# MB9BFD1xT register map
File version: 1.7
Registers are 32-bit, read-write, reset 0x0 unless marked. A register's access mark holds for its fields unless they carry their own. Offsets are from the block's base; [hi:lo] are bit positions; 'fields as' and 'values as' point back to an identical list.

## FLASH_IF — Flash Memory
Base 0x40000000
0x00 FASZR reset 0x2 — Flash Access Size Register
  [1:0] ASZ — Flash Access Size
0x04 FRWTR reset 0x2 — Flash Read Wait Register
  [1:0] RWT — Read Wait Cycle
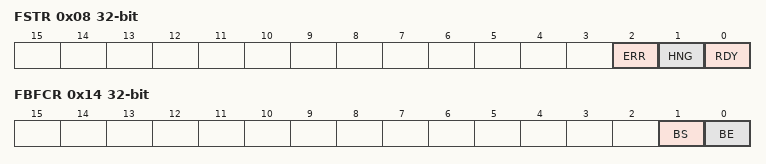
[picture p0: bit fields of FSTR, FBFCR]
0x08 FSTR ro — Flash Status Register
  [2] ERR rw — Flash ECC Error
  [1] HNG — Flash Hang flag
  [0] RDY — Flash Rdy
0x10 FSYNDN — Flash Sync Down Register
  [2:0] SD — Flash Sync
0x14 FBFCR — Flash Buffer Control Register
  [1] BS ro — Buffer Status
  [0] BE — Buffer Enable
0x100 CRTRMM ro reset not defined — CR Trimming Data Mirror Register
  [9:0] TRMM — CR Trimming Data Mirror

## CRTRIM — CR Trimming Registers
Base 0x4002E000
0x00 MCR_PSR 8-bit reset 0x1 — High-speed CR oscillation Frequency Division Setup Register
  [1:0] CSR — High-speed CR oscillation frequency division ratio setting bits
0x04 MCR_FTRM 16-bit reset 0x7F — High-speed CR oscillation Frequency Trimming Register
  [7:0] TRD — Frequency trimming setup bits
0x0C MCR_RLR reset 0x1 — High-Speed CR Oscillation Register Write-Protect Register
  [31:0] TRMLCK — Register write-protect bits

## SWWDT — Software Watchdog Timer
Base 0x40012000
0x00 WDOGLOAD reset 0xFFFFFFFF — Software Watchdog Timer Load Register
0x04 WDOGVALUE ro reset 0xFFFFFFFF — Software Watchdog Timer Value Register
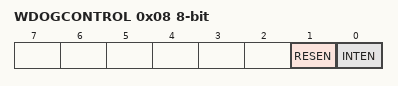
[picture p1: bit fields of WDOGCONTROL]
0x08 WDOGCONTROL 8-bit — Software Watchdog Timer Control Register
  [1] RESEN — Reset enable bit of the software watchdog
  [0] INTEN — Interrupt and counter enable bit of the software watchdog
0x0C WDOGINTCLR reset 0xFFFFFFFF — Software Watchdog Timer Clear Register
0x10 WDOGRIS 8-bit ro — Software Watchdog Timer Interrupt Status Register
  [0] RIS — Software watchdog interrupt status bit
0xC00 WDOGLOCK — Software Watchdog Timer Lock Register

## HWWDT — Hardware Watchdog Timer
Base 0x40011000
0x00 WDG_LDR reset 0xFFFF — Hardware Watchdog Timer Load Register
0x04 WDG_VLR ro — Hardware Watchdog Timer Value Register
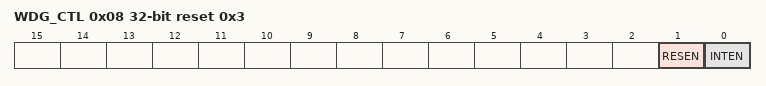
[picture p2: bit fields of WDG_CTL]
0x08 WDG_CTL reset 0x3 — Hardware Watchdog Timer Control Register
  [1] RESEN — Hardware watchdog reset enable bit
  [0] INTEN — Hardware watchdog interrupt and counter enable bit
0x0C WDG_ICL 8-bit reset 0xFF (reset mask 0x0) — Hardware Watchdog Timer Clear Register
0x10 WDG_RIS 1-bit ro reset 0xFF (reset mask 0x0) — Hardware Watchdog Timer Interrupt Status Register
  [0] RIS — Hardware watchdog interrupt status bit
0xC00 WDG_LCK reset 0x1 — Hardware Watchdog Timer Lock Register

## DTIM — Dual Timer
Base 0x40015000
0x00 TIMER1LOAD (DualTimer1 view) — Load Register
0x04 TIMER1VALUE ro reset 0xFFFFFFFF — Value Register
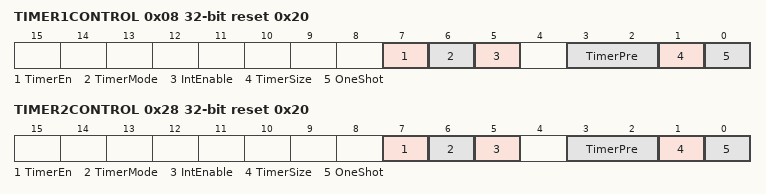
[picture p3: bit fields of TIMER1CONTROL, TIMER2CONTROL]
0x08 TIMER1CONTROL reset 0x20 — Control Register
  [7] TimerEn — Enable bit
  [6] TimerMode — Mode bit
  [5] IntEnable — Interrupt enable bit
  [3:2] TimerPre — Prescale bits
  [1] TimerSize — Counter size bit
  [0] OneShot — One-shot mode bit
0x0C TIMER1INTCLR wo reset not defined — Interrupt Clear Register
0x10 TIMER1RIS ro — Interrupt Status Register
  [0] TIMER1RIS — Interrupt Status Register bit
0x14 TIMER1MIS ro — Masked Interrupt Status Register
  [0] TIMER1MIS — Masked Interrupt Status bit
0x18 TIMER1BGLOAD — Background Load Register
0x20 TIMER2LOAD — Load Register
0x24 TIMER2VALUE ro reset 0xFFFFFFFF — Value Register
0x28 TIMER2CONTROL reset 0x20 — Control Register
  fields as TIMER1CONTROL
0x2C TIMER2INTCLR wo reset not defined — Interrupt Clear Register
0x30 TIMER2RIS ro — Interrupt Status Register
  [0] TIMER1RIS — Interrupt Status Register bit
0x34 TIMER2MIS ro — Masked Interrupt Status Register
  [0] TIMER1MIS — Masked Interrupt Status bit
0x38 TIMER2BGLOAD — Background Load Register

## BTIOSEL03 — Base Timer I/O Select
Base 0x40025100
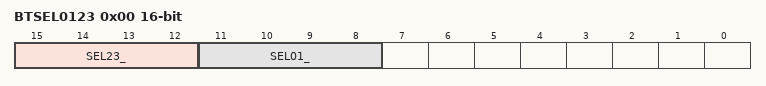
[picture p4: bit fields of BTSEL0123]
0x00 BTSEL0123 16-bit — I/O Select Register
  [15:12] SEL23_ — I/O select bits for Ch.2/Ch.3
  [11:8] SEL01_ — I/O select bits for Ch.0/Ch.1

## Notices in the file
Licence Terms
FUJITSU SEMICONDUCTOR LIMITED (gLICENSORh) hereby grants and
you (gLICENSEEh) hereby accept a non transferable, non-exclusive
licence to use and copy the deliverables (gDeliverablesh) solely for
the purpose of; (i) developing LICENSEEfs development tools and
distributing such development tools to third parties; (ii) generating
derivative representations of the Deliverables to develop and debug
software for LICENSORfs targeted devices or device series identified
within the Deliverables, (together the gPurposeh) under the following
terms and conditions:
1. Ownership.
The Deliverables are the property of LICENSOR. LICENSEE acquires no
right, title or interest in the Deliverables other than the licence
rights granted herein.
2. Use.
LICENSEE shall only be permitted to use the Deliverables for the
Purpose. LICENSEE shall not reverse engineer, decompile or
disassemble the Deliverables, in whole or in part.
3. Copies.
All copies of the Deliverables must bear the same notice(s) contained
on the original copies of the Deliverables.
4. No Warranty.
THE DELIVERABLES ARE PROVIDED gAS ISh AND ANY EXPRESS, IMPLIED OR
STATUTORY WARRANTIES, INCLUDING, BUT NOT LIMITED TO, THE IMPLIED
WARRANTIES OF MERCHANTABILITY, SATISFACTORY QUALITY AND FITNESS FOR
A PARTICULAR PURPOSE ARE DISCLAIMED.
IN NO EVENT SHALL LICENSOR BE LIABLE FOR ANY DIRECT, INDIRECT,
INCIDENTAL, SPECIAL, EXEMPLARY, OR CONSEQUENTIAL DAMAGES HOWEVER CAUSED
AND ON ANY THEORY OF LIABILITY, WHETHER IN CONTRACT, STRICT LIABILITY,
OR TORT (INCLUDING NEGLIGENCE OR OTHERWISE) ARISING IN ANY WAY OUT OF
THE USE OF THE DELIVERABLES, EVEN IF ADVISED OF THE POSSIBILITY OF SUCH
DAMAGE.
LICENSEE EXPRESSLY ASSUMES ALL LIABILITIES AND RISKS, FOR USE OR
OPERATION OF THE DELIVERABLES.
5.In the event that LICENSEE receives early access to the Deliverables,
LICENSEE acknowledges and agrees that;
(a) notwithstanding the licence grants above, LICENSEE shall only be
permitted to use the Deliverables solely internally for evaluation and
providing feedback to LICENSOR;
(b) except with respect to the limited licence grants in 5(a), LICENSEE
shall be subject to all of the terms and conditions set out above; and
(c) the Deliverables are confidential information and LICENSEE shall
maintain in confidence the Deliverables and apply security measures no
less stringent than the measures that LICENSEE applies to its own like
information, but not less than a reasonable degree of care, to prevent
unauthorised disclosure and use of the Deliverables.
